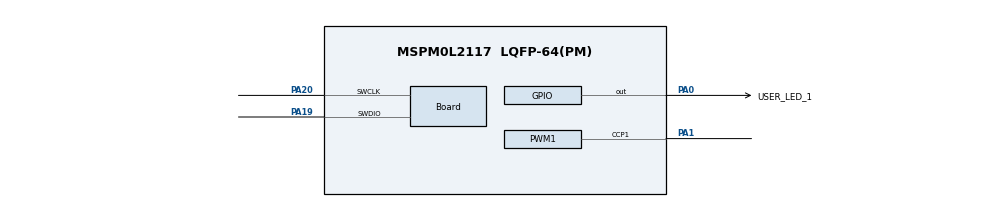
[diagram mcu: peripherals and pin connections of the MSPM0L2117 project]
//@cliArgs --device "MSPM0L211X" --part "Default" --package "LQFP-64(PM)" 
//@v2CliArgs --device "MSPM0L2117" --package "LQFP-64(PM)" 
// @cliArgs --board /ti/boards/LP_MSPM0L2117 --rtos nortos

/**
 * Import the modules used in this configuration.
 */
const GPIO   = scripting.addModule("/ti/driverlib/GPIO", {}, false);
const GPIO1  = GPIO.addInstance();
const PWM    = scripting.addModule("/ti/driverlib/PWM", {}, false);
const PWM1   = PWM.addInstance();
const SYSCTL = scripting.addModule("/ti/driverlib/SYSCTL");

/**
 * Write custom configuration values to the imported modules.
 */
GPIO1.$name                          = "GPIO_LEDS";
GPIO1.associatedPins[0].$name        = "USER_LED_1";
GPIO1.associatedPins[0].assignedPort = "PORTA";
GPIO1.associatedPins[0].assignedPin  = "0";
GPIO1.associatedPins[0].initialValue = "SET";
GPIO1.associatedPins[0].pin.$assign  = "PA0";

const Board                       = scripting.addModule("/ti/driverlib/Board", {}, false);
Board.peripheral.$assign          = "DEBUGSS";
Board.peripheral.swclkPin.$assign = "PA20";
Board.peripheral.swdioPin.$assign = "PA19";

PWM1.$name                      = "PWM_0";
PWM1.ccIndex                    = [1];
PWM1.pwmMode                    = "EDGE_ALIGN_UP";
PWM1.clockSource                = "MFCLK";
PWM1.timerCount                 = 1;
PWM1.interrupts                 = ["ZERO_EVENT"];
PWM1.peripheral.$assign         = "TIMG14";
PWM1.peripheral.ccp1Pin.$assign = "PA1";
PWM1.PWM_CHANNEL_1.$name        = "ti_driverlib_pwm_PWMTimerCC0";
PWM1.PWM_CHANNEL_1.initVal      = "HIGH";
PWM1.PWM_CHANNEL_1.invert       = true;

SYSCTL.MFCLKEn            = true;
SYSCTL.peripheral.$assign = "SYSCTL";

const ProjectConfig              = scripting.addModule("/ti/project_config/ProjectConfig", {}, false);
ProjectConfig.migrationCondition = true;
